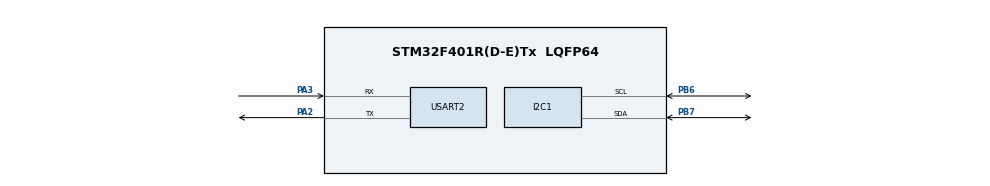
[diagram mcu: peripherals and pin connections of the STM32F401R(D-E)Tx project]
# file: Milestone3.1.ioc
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Mcu.Family=STM32F4
Mcu.Name=STM32F401R(D-E)Tx
Mcu.Package=LQFP64
NVIC.PriorityGroup=NVIC_PRIORITYGROUP_4
PA2.Mode=Asynchronous
PA2.Signal=USART2_TX
PA3.Mode=Asynchronous
PA3.Signal=USART2_RX
PB6.Mode=I2C
PB6.Signal=I2C1_SCL
PB7.Mode=I2C
PB7.Signal=I2C1_SDA
ProjectManager.HeapSize=0x200
ProjectManager.StackSize=0x400
ProjectManager.TargetToolchain=Makefile
RCC.AHBFreq_Value=16000000
RCC.APB1Freq_Value=16000000
RCC.APB2Freq_Value=16000000
RCC.CortexFreq_Value=16000000
RCC.HSE_VALUE=25000000
RCC.HSI_VALUE=16000000
RCC.LSE_VALUE=32768
RCC.SYSCLKFreq_VALUE=16000000
RCC.VCOOutputFreq_Value=192000000
USART2.VirtualMode=VM_ASYNC
board=custom

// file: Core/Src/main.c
/* USER CODE BEGIN Header */
/**
  ******************************************************************************
  * @file           : main.c
  * @brief          : Main program body
  ******************************************************************************
  * @attention
  *
  * Copyright (c) 2026 STMicroelectronics.
  * All rights reserved.
  *
  * This software is licensed under terms that can be found in the LICENSE file
  * in the root directory of this software component.
  * If no LICENSE file comes with this software, it is provided AS-IS.
  *
  ******************************************************************************
  */
/* USER CODE END Header */
#include "main.h"
#include <string.h>

void SystemClock_Config(void);
static void MX_GPIO_Init(void);
static void MX_I2C1_Init(void);
static void MX_USART2_UART_Init(void);
/* USER CODE BEGIN PFP */

typedef enum {
  ERROR_TIMEOUT,
  ERROR_NACK,
  ERROR_BUS_STUCK,
  I2C_SUCCESS
} I2C_Status;

I2C_Status I2C_Wait_With_Timeout(uint32_t, uint32_t);
/* USER CODE END PFP */

int main(void)
{

  /* MCU Configuration--------------------------------------------------------*/

  /* Reset of all peripherals, Initializes the Flash interface and the Systick. */
  LL_APB2_GRP1_EnableClock(LL_APB2_GRP1_PERIPH_SYSCFG);
  LL_APB1_GRP1_EnableClock(LL_APB1_GRP1_PERIPH_PWR);

  /* System interrupt init*/
  NVIC_SetPriorityGrouping(NVIC_PRIORITYGROUP_4);

  /* SysTick_IRQn interrupt configuration */
  NVIC_SetPriority(SysTick_IRQn, NVIC_EncodePriority(NVIC_GetPriorityGrouping(),15, 0));

  /* Configure the system clock */
  SystemClock_Config();

  CoreDebug->DEMCR |= CoreDebug_DEMCR_TRCENA_Msk;

  DWT->CYCCNT = 0;

  /* Initialize all configured peripherals */

  MX_GPIO_Init();
  MX_I2C1_Init();
  MX_USART2_UART_Init();

  const char *msg = "System booting..\n";
  UART_SendAndReadData(USART2, (const uint8_t *)msg, strlen(msg));
  if (!LL_I2C_IsEnabled(I2C1)){
      LL_I2C_Enable(I2C1);
    }
  /* Infinite loop */
  /* USER CODE BEGIN WHILE */
  while (1)
  {
    msg = "Still working..\n";
      UART_SendAndReadData(USART2, (const uint8_t *)msg, strlen(msg));
    /* USER CODE END WHILE */
   // while (LL_I2C_IsActiveFlag_BUSY(I2C1)){
      /*
      I2C_Bus_Recovery();
      if (LL_I2C_IsActiveFlag_BUSY(I2C1)){
        msg = "Bus Stuck Error. (ERROR_BUS_STUCK FLAG)\n";
        UART_SendAndReadData(USART2, (const uint8_t *)msg, strlen(msg));
        LL_mDelay(50);
        continue;
      }
        */
    //}
    msg = "Still workingx2..\n";
      UART_SendAndReadData(USART2, (const uint8_t *)msg, strlen(msg));

    LL_I2C_GenerateStartCondition(I2C1);

    msg = "Still workingx3..\n";
      UART_SendAndReadData(USART2, (const uint8_t *)msg, strlen(msg));
    if (I2C_Wait_With_Timeout(LL_I2C_SR1_SB, 14400) == ERROR_TIMEOUT){
      msg = "Timeout Error. (ERROR_TIMEOUT FLAG)\n";
      UART_SendAndReadData(USART2, (const uint8_t *)msg, strlen(msg));
      LL_I2C_GenerateStopCondition(I2C1);
      LL_mDelay(50);
      continue;
    }
    msg = "Still workingx4..\n";
      UART_SendAndReadData(USART2, (const uint8_t *)msg, strlen(msg));

  //  while (!LL_I2C_IsActiveFlag_SB(I2C1)){}
    msg = "Still workingx5..\n";
      UART_SendAndReadData(USART2, (const uint8_t *)msg, strlen(msg));

    volatile uint8_t shifted = 0x48 << 1;
    LL_I2C_TransmitData8(I2C1, shifted);
    shifted = 0x00;

   // while (!LL_I2C_IsActiveFlag_ADDR(I2C1) && !LL_I2C_IsActiveFlag_AF(I2C1)){}

    if (I2C_Wait_With_Timeout(LL_I2C_SR1_ADDR, 14400) == ERROR_NACK){
      msg = "NACK Error. (ERROR_NACK FLAG)\n";
      UART_SendAndReadData(USART2, (const uint8_t *)msg, strlen(msg));
      LL_I2C_GenerateStopCondition(I2C1);
      LL_mDelay(50);
      continue;
    }
  // waits until either condition is reached

  // failed condition, no address detected

      // an address was detected!
      LL_I2C_ClearFlag_ADDR(I2C1);

      LL_I2C_TransmitData8(I2C1, shifted);

     /* if (I2C_Wait_With_Timeout(LL_I2C_SR1_TXE, 14400) != I2C_SUCCESS){
        msg = "First Byte Transmission Failed. \n";
        UART_SendAndReadData(USART2, (const uint8_t *)msg, strlen(msg));
        LL_I2C_GenerateStopCondition(I2C1);
        LL_mDelay(50);
        continue;
   */   }

      // while(!LL_I2C_IsActiveFlag_BTF(I2C1)){}

      LL_I2C_TransmitData8(I2C1, 0x69);

      if (I2C_Wait_With_Timeout(LL_I2C_SR1_TXE, 14400) != I2C_SUCCESS){
        msg = "Second Byte Transmission Failed. \n";
        UART_SendAndReadData(USART2, (const uint8_t *)msg, strlen(msg));
        LL_I2C_GenerateStopCondition(I2C1);
        LL_mDelay(50);
      }

      // add code check here
      msg = "Success! \n";
      UART_SendAndReadData(USART2, (const uint8_t *)msg, strlen(msg));
      LL_mDelay(50);

      LL_I2C_GenerateStopCondition(I2C1);
      // while(!LL_I2C_IsActiveFlag_STOP(I2C1));

      while(LL_I2C_IsActiveFlag_BUSY(I2C1)){}
      // LL_GPIO_SetOutputPin(GPIOA, LL_GPIO_PIN_5);
      LL_mDelay(50);
      }

void UART_SendAndReadData(USART_TypeDef *USARTX, const uint8_t *data, size_t length){

  for (size_t i = 0; i < length; i++){
   while (!LL_USART_IsActiveFlag_TXE(USARTX));
   LL_USART_TransmitData8(USARTX, data[i]);
   //while(!LL_USART_IsActiveFlag_RXNE(USART1)){}
  //  LL_USART_ReceiveData8(USART1);
  }
  while (!LL_USART_IsActiveFlag_TC(USARTX)){}
  //while(!LL_USART_IsActiveFlag_RXNE(USART1)){}
  //LL_USART_ReceiveData8(USART1);
}

void I2C_Bus_Recovery(){

      LL_GPIO_SetPinMode(GPIOB, LL_GPIO_PIN_6, LL_GPIO_MODE_OUTPUT);
      LL_GPIO_SetPinMode(GPIOB, LL_GPIO_PIN_7, LL_GPIO_MODE_INPUT);

      for (int i = 0; i < 9; i++){
        LL_GPIO_ResetOutputPin(GPIOB, LL_GPIO_PIN_6);
        LL_mDelay(50);
        LL_GPIO_SetOutputPin(GPIOB, LL_GPIO_PIN_6);
        LL_mDelay(50);
        if (LL_GPIO_IsInputPinSet(GPIOB, LL_GPIO_PIN_7)){
          break;
        }

      }
      LL_GPIO_SetPinMode(GPIOB, LL_GPIO_PIN_6, LL_GPIO_MODE_ALTERNATE);
      LL_GPIO_SetPinMode(GPIOB, LL_GPIO_PIN_7, LL_GPIO_MODE_ALTERNATE);

      LL_GPIO_SetAFPin_0_7(GPIOB, LL_GPIO_PIN_6, LL_GPIO_AF_4);
      LL_GPIO_SetAFPin_0_7(GPIOB, LL_GPIO_PIN_7, LL_GPIO_AF_4);
}

I2C_Status I2C_Wait_With_Timeout(uint32_t Flag, uint32_t TimeoutCycles){
  uint32_t start_cycle = DWT-> CYCCNT;

  while ((I2C1 ->SR1 & Flag)==0){

    if ((DWT->CYCCNT) - start_cycle >= TimeoutCycles){
      return ERROR_TIMEOUT;
    }

    else if (LL_I2C_IsActiveFlag_AF(I2C1)){
      LL_I2C_ClearFlag_AF(I2C1);

      LL_I2C_IsActiveFlag_AF(I2C1);

      return ERROR_NACK;
    }
  }

  return I2C_SUCCESS;
}

void SystemClock_Config(void)
{
  LL_FLASH_SetLatency(LL_FLASH_LATENCY_0);
  while(LL_FLASH_GetLatency()!= LL_FLASH_LATENCY_0)
  {
  }
  LL_PWR_SetRegulVoltageScaling(LL_PWR_REGU_VOLTAGE_SCALE2);
  LL_RCC_HSI_SetCalibTrimming(16);
  LL_RCC_HSI_Enable();

   /* Wait till HSI is ready */
  while(LL_RCC_HSI_IsReady() != 1)
  {

  }
  LL_RCC_SetAHBPrescaler(LL_RCC_SYSCLK_DIV_1);
  LL_RCC_SetAPB1Prescaler(LL_RCC_APB1_DIV_1);
  LL_RCC_SetAPB2Prescaler(LL_RCC_APB2_DIV_1);
  LL_RCC_SetSysClkSource(LL_RCC_SYS_CLKSOURCE_HSI);

   /* Wait till System clock is ready */
  while(LL_RCC_GetSysClkSource() != LL_RCC_SYS_CLKSOURCE_STATUS_HSI)
  {

  }
  LL_Init1msTick(16000000);
  LL_SetSystemCoreClock(16000000);
  LL_RCC_SetTIMPrescaler(LL_RCC_TIM_PRESCALER_TWICE);
}

static void MX_I2C1_Init(void)
{

  LL_I2C_InitTypeDef I2C_InitStruct = {0};

  LL_GPIO_InitTypeDef GPIO_InitStruct = {0};

  LL_AHB1_GRP1_EnableClock(LL_AHB1_GRP1_PERIPH_GPIOB);
  /**I2C1 GPIO Configuration
  PB6   ------> I2C1_SCL
  PB7   ------> I2C1_SDA
  */
  GPIO_InitStruct.Pin = LL_GPIO_PIN_6|LL_GPIO_PIN_7;
  GPIO_InitStruct.Mode = LL_GPIO_MODE_ALTERNATE;
  GPIO_InitStruct.Speed = LL_GPIO_SPEED_FREQ_VERY_HIGH;
  GPIO_InitStruct.OutputType = LL_GPIO_OUTPUT_OPENDRAIN;
  GPIO_InitStruct.Pull = LL_GPIO_PULL_NO;
  GPIO_InitStruct.Alternate = LL_GPIO_AF_4;
  LL_GPIO_Init(GPIOB, &GPIO_InitStruct);

  /* Peripheral clock enable */
  LL_APB1_GRP1_EnableClock(LL_APB1_GRP1_PERIPH_I2C1);

  /** I2C Initialization
  */
  LL_I2C_DisableOwnAddress2(I2C1);
  LL_I2C_DisableGeneralCall(I2C1);
  LL_I2C_EnableClockStretching(I2C1);
  I2C_InitStruct.PeripheralMode = LL_I2C_MODE_I2C;
  I2C_InitStruct.ClockSpeed = 100000;
  I2C_InitStruct.DutyCycle = LL_I2C_DUTYCYCLE_2;
  I2C_InitStruct.OwnAddress1 = 0;
  I2C_InitStruct.TypeAcknowledge = LL_I2C_ACK;
  I2C_InitStruct.OwnAddrSize = LL_I2C_OWNADDRESS1_7BIT;
  LL_I2C_Init(I2C1, &I2C_InitStruct);
  LL_I2C_SetOwnAddress2(I2C1, 0);

}

static void MX_USART2_UART_Init(void)
{

  LL_USART_InitTypeDef USART_InitStruct = {0};

  LL_GPIO_InitTypeDef GPIO_InitStruct = {0};

  /* Peripheral clock enable */
  LL_APB1_GRP1_EnableClock(LL_APB1_GRP1_PERIPH_USART2);

  LL_AHB1_GRP1_EnableClock(LL_AHB1_GRP1_PERIPH_GPIOA);
  /**USART2 GPIO Configuration
  PA2   ------> USART2_TX
  PA3   ------> USART2_RX
  */
  GPIO_InitStruct.Pin = LL_GPIO_PIN_2|LL_GPIO_PIN_3;
  GPIO_InitStruct.Mode = LL_GPIO_MODE_ALTERNATE;
  GPIO_InitStruct.Speed = LL_GPIO_SPEED_FREQ_VERY_HIGH;
  GPIO_InitStruct.OutputType = LL_GPIO_OUTPUT_PUSHPULL;
  GPIO_InitStruct.Pull = LL_GPIO_PULL_NO;
  GPIO_InitStruct.Alternate = LL_GPIO_AF_7;
  LL_GPIO_Init(GPIOA, &GPIO_InitStruct);

  USART_InitStruct.BaudRate = 115200;
  USART_InitStruct.DataWidth = LL_USART_DATAWIDTH_8B;
  USART_InitStruct.StopBits = LL_USART_STOPBITS_1;
  USART_InitStruct.Parity = LL_USART_PARITY_NONE;
  USART_InitStruct.TransferDirection = LL_USART_DIRECTION_TX_RX;
  USART_InitStruct.HardwareFlowControl = LL_USART_HWCONTROL_NONE;
  USART_InitStruct.OverSampling = LL_USART_OVERSAMPLING_16;
  LL_USART_Init(USART2, &USART_InitStruct);
  LL_USART_ConfigAsyncMode(USART2);
  LL_USART_Enable(USART2);

}

static void MX_GPIO_Init(void)
{

  /* GPIO Ports Clock Enable */
  LL_AHB1_GRP1_EnableClock(LL_AHB1_GRP1_PERIPH_GPIOA);
  LL_AHB1_GRP1_EnableClock(LL_AHB1_GRP1_PERIPH_GPIOB);

}

void Error_Handler(void)
{
  __disable_irq();
  while (1)
  {
  }
}
